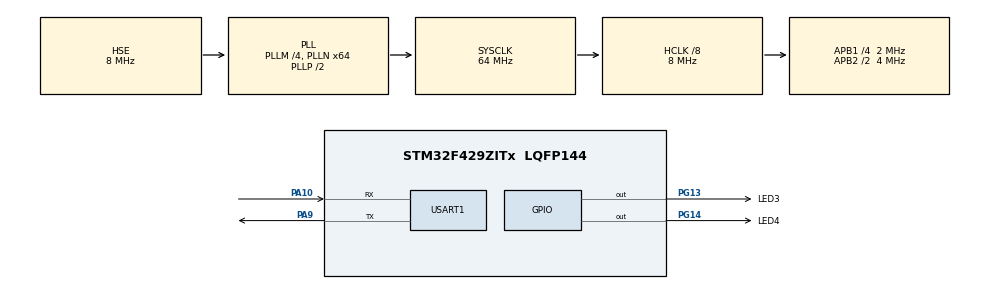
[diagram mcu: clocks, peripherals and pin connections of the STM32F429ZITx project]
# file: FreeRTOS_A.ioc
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FREERTOS.Tasks01=defaultTask,0,128,StartDefaultTask,Default,NULL,Dynamic,NULL,NULL;Task1,-3,128,vTask1,Default,NULL,Dynamic,NULL,NULL;Task2,-3,128,vTask2,Default,NULL,Dynamic,NULL,NULL
Mcu.Family=STM32F4
Mcu.Name=STM32F429ZITx
Mcu.Package=LQFP144
NVIC.PriorityGroup=NVIC_PRIORITYGROUP_4
NVIC.TIM6_DAC_IRQn=true\:0\:0\:false\:false\:true\:false\:false\:true
NVIC.TimeBase=TIM6_DAC_IRQn
NVIC.TimeBaseIP=TIM6
PA10.Mode=Asynchronous
PA10.Signal=USART1_RX
PA13.Mode=Trace_Asynchronous_SW
PA13.Signal=SYS_JTMS-SWDIO
PA14.Mode=Trace_Asynchronous_SW
PA14.Signal=SYS_JTCK-SWCLK
PA9.Mode=Asynchronous
PA9.Signal=USART1_TX
PB3.Mode=Trace_Asynchronous_SW
PB3.Signal=SYS_JTDO-SWO
PG13.GPIO_Label=LED3
PG13.Signal=GPIO_Output
PG14.GPIO_Label=LED4
PG14.Signal=GPIO_Output
PH0/OSC_IN.Mode=HSE-External-Oscillator
PH0/OSC_IN.Signal=RCC_OSC_IN
PH1/OSC_OUT.Mode=HSE-External-Oscillator
PH1/OSC_OUT.Signal=RCC_OSC_OUT
ProjectManager.HeapSize=0x200
ProjectManager.StackSize=0x400
ProjectManager.TargetToolchain=TrueSTUDIO
RCC.48MHZClocksFreq_Value=32000000
RCC.AHBCLKDivider=RCC_SYSCLK_DIV8
RCC.AHBFreq_Value=8000000
RCC.APB1CLKDivider=RCC_HCLK_DIV4
RCC.APB1Freq_Value=2000000
RCC.APB1TimFreq_Value=4000000
RCC.APB2CLKDivider=RCC_HCLK_DIV2
RCC.APB2Freq_Value=4000000
RCC.APB2TimFreq_Value=8000000
RCC.CortexFreq_Value=8000000
RCC.HCLKFreq_Value=8000000
RCC.HSE_VALUE=8000000
RCC.HSI_VALUE=16000000
RCC.LSE_VALUE=32768
RCC.PLLM=4
RCC.PLLN=64
RCC.PLLSourceVirtual=RCC_PLLSOURCE_HSE
RCC.SYSCLKFreq_VALUE=64000000
RCC.SYSCLKSource=RCC_SYSCLKSOURCE_PLLCLK
RCC.VCOOutputFreq_Value=128000000
USART1.VirtualMode=VM_ASYNC
VP_FREERTOS_VS_CMSIS_V1.Mode=CMSIS_V1
VP_SYS_VS_tim6.Mode=TIM6
board=custom

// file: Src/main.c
/* USER CODE BEGIN Header */
/**
  ******************************************************************************
  * @file           : main.c
  * @brief          : Main program body
  ******************************************************************************
  * @attention
  *
  * <h2><center>&copy; Copyright (c) 2019 STMicroelectronics.
  * All rights reserved.</center></h2>
  *
  * This software component is licensed by ST under BSD 3-Clause license,
  * the "License"; You may not use this file except in compliance with the
  * License. You may obtain a copy of the License at:
  *                        opensource.org/licenses/BSD-3-Clause
  *
  ******************************************************************************
  */
/* USER CODE END Header */

#include "main.h"
#include "cmsis_os.h"

/* USER CODE BEGIN Includes */
#include <string.h>
#include <stdio.h>
/* USER CODE END Includes */

/* USER CODE BEGIN PD */
#define mainDELAY_LOOP_COUNT    (1000)
/* USER CODE END PD */

UART_HandleTypeDef huart1;

osThreadId defaultTaskHandle;
osThreadId Task1Handle;
osThreadId Task2Handle;

void SystemClock_Config(void);
static void MX_GPIO_Init(void);
static void MX_USART1_UART_Init(void);
void StartDefaultTask(void const * argument);
void vTask1(void const * argument);
void vTask2(void const * argument);

/* USER CODE BEGIN 0 */

  char sMessage1[] = "This is Task1 \r \n";
  char sMessage2[] = "This is Task2 \r \n";
/* USER CODE END 0 */

int main(void)
{

  /* MCU Configuration--------------------------------------------------------*/

  /* Reset of all peripherals, Initializes the Flash interface and the Systick. */
  HAL_Init();

  /* Configure the system clock */
  SystemClock_Config();

  /* Initialize all configured peripherals */
  MX_GPIO_Init();
  MX_USART1_UART_Init();
  /* USER CODE BEGIN 2 */
  //HAL_TIM_Base_Start_IT(&htim7);
  /* USER CODE END 2 */

  /* Create the thread(s) */
  /* definition and creation of defaultTask */
  osThreadDef(defaultTask, StartDefaultTask, osPriorityNormal, 0, 128);
  defaultTaskHandle = osThreadCreate(osThread(defaultTask), NULL);

  /* definition and creation of Task1 */
  osThreadDef(Task1, vTask1, osPriorityIdle, 0, 128);
  Task1Handle = osThreadCreate(osThread(Task1), NULL);

  /* definition and creation of Task2 */
  osThreadDef(Task2, vTask2, osPriorityIdle, 0, 128);
  Task2Handle = osThreadCreate(osThread(Task2), NULL);

  /* Start scheduler */
  osKernelStart();

  /* We should never get here as control is now taken by the scheduler */

  /* Infinite loop */
  while (1)
  {

    /* USER CODE BEGIN 3 */
    //void StartTask02(void const* argument);

  }
  /* USER CODE END 3 */
}

void SystemClock_Config(void)
{
  RCC_OscInitTypeDef RCC_OscInitStruct = {0};
  RCC_ClkInitTypeDef RCC_ClkInitStruct = {0};

  /** Configure the main internal regulator output voltage
  */
  __HAL_RCC_PWR_CLK_ENABLE();
  __HAL_PWR_VOLTAGESCALING_CONFIG(PWR_REGULATOR_VOLTAGE_SCALE3);
  /** Initializes the CPU, AHB and APB busses clocks
  */
  RCC_OscInitStruct.OscillatorType = RCC_OSCILLATORTYPE_HSE;
  RCC_OscInitStruct.HSEState = RCC_HSE_ON;
  RCC_OscInitStruct.PLL.PLLState = RCC_PLL_ON;
  RCC_OscInitStruct.PLL.PLLSource = RCC_PLLSOURCE_HSE;
  RCC_OscInitStruct.PLL.PLLM = 4;
  RCC_OscInitStruct.PLL.PLLN = 64;
  RCC_OscInitStruct.PLL.PLLP = RCC_PLLP_DIV2;
  RCC_OscInitStruct.PLL.PLLQ = 4;
  if (HAL_RCC_OscConfig(&RCC_OscInitStruct) != HAL_OK)
  {
    Error_Handler();
  }
  /** Initializes the CPU, AHB and APB busses clocks
  */
  RCC_ClkInitStruct.ClockType = RCC_CLOCKTYPE_HCLK|RCC_CLOCKTYPE_SYSCLK
                              |RCC_CLOCKTYPE_PCLK1|RCC_CLOCKTYPE_PCLK2;
  RCC_ClkInitStruct.SYSCLKSource = RCC_SYSCLKSOURCE_PLLCLK;
  RCC_ClkInitStruct.AHBCLKDivider = RCC_SYSCLK_DIV8;
  RCC_ClkInitStruct.APB1CLKDivider = RCC_HCLK_DIV4;
  RCC_ClkInitStruct.APB2CLKDivider = RCC_HCLK_DIV2;

  if (HAL_RCC_ClockConfig(&RCC_ClkInitStruct, FLASH_LATENCY_0) != HAL_OK)
  {
    Error_Handler();
  }
}

static void MX_USART1_UART_Init(void)
{

  huart1.Instance = USART1;
  huart1.Init.BaudRate = 115200;
  huart1.Init.WordLength = UART_WORDLENGTH_8B;
  huart1.Init.StopBits = UART_STOPBITS_1;
  huart1.Init.Parity = UART_PARITY_NONE;
  huart1.Init.Mode = UART_MODE_TX_RX;
  huart1.Init.HwFlowCtl = UART_HWCONTROL_NONE;
  huart1.Init.OverSampling = UART_OVERSAMPLING_16;
  if (HAL_UART_Init(&huart1) != HAL_OK)
  {
    Error_Handler();
  }

}

static void MX_GPIO_Init(void)
{
  GPIO_InitTypeDef GPIO_InitStruct = {0};

  /* GPIO Ports Clock Enable */
  __HAL_RCC_GPIOH_CLK_ENABLE();
  __HAL_RCC_GPIOA_CLK_ENABLE();
  __HAL_RCC_GPIOG_CLK_ENABLE();
  __HAL_RCC_GPIOB_CLK_ENABLE();

  /*Configure GPIO pin Output Level */
  HAL_GPIO_WritePin(GPIOG, LED3_Pin|LED4_Pin, GPIO_PIN_RESET);

  /*Configure GPIO pins : LED3_Pin LED4_Pin */
  GPIO_InitStruct.Pin = LED3_Pin|LED4_Pin;
  GPIO_InitStruct.Mode = GPIO_MODE_OUTPUT_PP;
  GPIO_InitStruct.Pull = GPIO_NOPULL;
  GPIO_InitStruct.Speed = GPIO_SPEED_FREQ_LOW;
  HAL_GPIO_Init(GPIOG, &GPIO_InitStruct);

}

void StartDefaultTask(void const * argument)
{

  for(;;)
  {
    osDelay(1);
  }
}

void vTask1(void const * argument)
{
  /* USER CODE BEGIN vTask1 */
	volatile unsigned long ul;

  /* Infinite loop */
  for(;;)
  {
   	HAL_GPIO_WritePin(LED4_GPIO_Port, LED4_Pin, GPIO_PIN_RESET);
  	HAL_GPIO_WritePin(LED3_GPIO_Port, LED3_Pin, GPIO_PIN_SET);
    //HAL_GPIO_TogglePin(LED3_GPIO_Port, LED3_Pin);
    HAL_UART_Transmit(&huart1, (uint8_t*)&sMessage1[0], (uint16_t)strlen(&sMessage1[0]), (uint32_t)0xFFFFFFFF);

    //for(ul = 0; ul < mainDELAY_LOOP_COUNT; ul++);
    osDelay(1);
    //HAL_GPIO_WritePin(LED3_GPIO_Port, LED3_Pin, GPIO_PIN_RESET);
  }
  /* USER CODE END vTask1 */
}

void vTask2(void const * argument)
{
  /* USER CODE BEGIN vTask2 */
	volatile unsigned long ul;

  /* Infinite loop */
  for(;;)
  {
		//osDelay(250);
  	HAL_GPIO_WritePin(LED3_GPIO_Port, LED3_Pin, GPIO_PIN_RESET);
		HAL_GPIO_WritePin(LED4_GPIO_Port, LED4_Pin, GPIO_PIN_SET);
		//HAL_GPIO_TogglePin(LED3_GPIO_Port, LED3_Pin);
		HAL_UART_Transmit(&huart1, (uint8_t*)&sMessage1[0], (uint16_t)strlen(&sMessage1[0]), (uint32_t)0xFFFFFFFF);

		//for(ul = 0; ul < mainDELAY_LOOP_COUNT; ul++);
		osDelay(1);
		//HAL_GPIO_WritePin(LED4_GPIO_Port, LED4_Pin, GPIO_PIN_RESET);
  }
  /* USER CODE END vTask2 */
}

void HAL_TIM_PeriodElapsedCallback(TIM_HandleTypeDef *htim)
{
  if (htim->Instance == TIM6) {
    HAL_IncTick();
  }
}

void Error_Handler(void)
{
}

/************************ (C) COPYRIGHT STMicroelectronics *****END OF FILE****/
